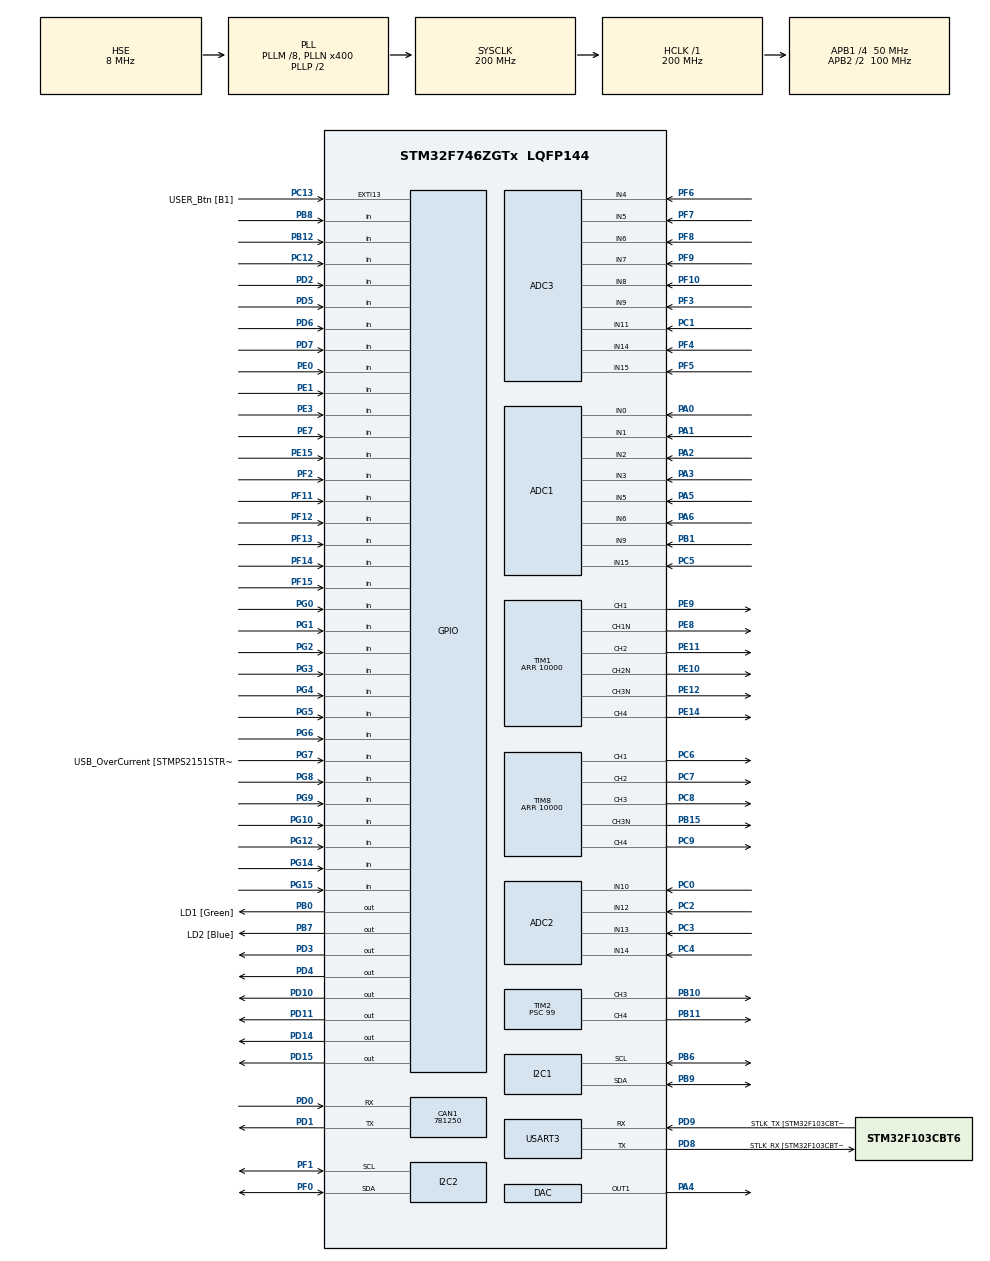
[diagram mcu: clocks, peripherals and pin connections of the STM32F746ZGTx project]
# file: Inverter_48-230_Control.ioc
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ADC1.Channel-0\#ChannelRegularConversion=ADC_CHANNEL_5
ADC1.ClockPrescaler=ADC_CLOCK_SYNC_PCLK_DIV6
ADC1.ContinuousConvMode=DISABLE
ADC1.DMAContinuousRequests=ENABLE
ADC1.DataAlign=ADC_DATAALIGN_RIGHT
ADC1.DiscontinuousConvMode=DISABLE
ADC1.EOCSelection=ADC_EOC_SEQ_CONV
ADC1.ExternalTrigConv=ADC_EXTERNALTRIGCONV_T1_TRGO2
ADC1.Mode=ADC_TRIPLEMODE_REGSIMULT
ADC1.NbrOfConversion=1
ADC1.NbrOfConversionFlag=1
ADC1.Rank-0\#ChannelRegularConversion=1
ADC1.SamplingTime-0\#ChannelRegularConversion=ADC_SAMPLETIME_15CYCLES
ADC1.ScanConvMode=ADC_SCAN_ENABLE
ADC1.master=1
ADC2.Channel-1\#ChannelRegularConversion=ADC_CHANNEL_14
ADC2.ClockPrescaler=ADC_CLOCK_SYNC_PCLK_DIV6
ADC2.DMAAccessMode=ADC_DMAACCESSMODE_1
ADC2.DataAlign=ADC_DATAALIGN_RIGHT
ADC2.EOCSelection=ADC_EOC_SEQ_CONV
ADC2.Mode=ADC_TRIPLEMODE_REGSIMULT
ADC2.NbrOfConversion=1
ADC2.NbrOfConversionFlag=1
ADC2.Rank-1\#ChannelRegularConversion=1
ADC2.SamplingTime-1\#ChannelRegularConversion=ADC_SAMPLETIME_15CYCLES
ADC2.ScanConvMode=ADC_SCAN_ENABLE
ADC3.Channel-1\#ChannelRegularConversion=ADC_CHANNEL_4
ADC3.ClockPrescaler=ADC_CLOCK_SYNC_PCLK_DIV6
ADC3.DMAAccessMode=ADC_DMAACCESSMODE_1
ADC3.DataAlign=ADC_DATAALIGN_RIGHT
ADC3.EOCSelection=ADC_EOC_SEQ_CONV
ADC3.Mode=ADC_TRIPLEMODE_REGSIMULT
ADC3.NbrOfConversion=1
ADC3.NbrOfConversionFlag=1
ADC3.Rank-1\#ChannelRegularConversion=1
ADC3.SamplingTime-1\#ChannelRegularConversion=ADC_SAMPLETIME_15CYCLES
ADC3.ScanConvMode=ADC_SCAN_ENABLE
CAN1.BS1=CAN_BS1_2TQ
CAN1.CalculateBaudRate=781250
CAN1.CalculateTimeBit=1280
CAN1.CalculateTimeQuantum=320.0
CORTEX_M7.ART_ACCELERATOR_ENABLE=1
CORTEX_M7.CPU_ICache=Enabled
CORTEX_M7.PREFETCH_ENABLE=1
Dma.ADC1.0.Direction=DMA_PERIPH_TO_MEMORY
Dma.ADC1.0.FIFOMode=DMA_FIFOMODE_DISABLE
Dma.ADC1.0.Instance=DMA2_Stream4
Dma.ADC1.0.MemDataAlignment=DMA_MDATAALIGN_HALFWORD
Dma.ADC1.0.MemInc=DMA_MINC_ENABLE
Dma.ADC1.0.Mode=DMA_CIRCULAR
Dma.ADC1.0.PeriphDataAlignment=DMA_PDATAALIGN_HALFWORD
Dma.ADC1.0.PeriphInc=DMA_PINC_DISABLE
Dma.ADC1.0.Priority=DMA_PRIORITY_LOW
Dma.Request0=ADC1
Dma.Request1=USART3_TX
Dma.USART3_TX.1.Direction=DMA_MEMORY_TO_PERIPH
Dma.USART3_TX.1.FIFOMode=DMA_FIFOMODE_DISABLE
Dma.USART3_TX.1.Instance=DMA1_Stream4
Dma.USART3_TX.1.MemDataAlignment=DMA_MDATAALIGN_BYTE
Dma.USART3_TX.1.MemInc=DMA_MINC_ENABLE
Dma.USART3_TX.1.Mode=DMA_NORMAL
Dma.USART3_TX.1.PeriphDataAlignment=DMA_PDATAALIGN_BYTE
Dma.USART3_TX.1.PeriphInc=DMA_PINC_DISABLE
Dma.USART3_TX.1.Priority=DMA_PRIORITY_LOW
I2C1.Timing=0x00C0EAFF
I2C2.Timing=0x00C0EAFF
Mcu.Family=STM32F7
Mcu.Name=STM32F746ZGTx
Mcu.Package=LQFP144
NVIC.DMA1_Stream4_IRQn=true\:0\:0\:false\:false\:true\:false\:true\:true
NVIC.DMA2_Stream4_IRQn=true\:0\:0\:false\:false\:true\:false\:true\:true
NVIC.PriorityGroup=NVIC_PRIORITYGROUP_4
NVIC.TIM8_TRG_COM_TIM14_IRQn=true\:7\:0\:true\:false\:true\:true\:true\:true
NVIC.USART3_IRQn=true\:0\:0\:false\:false\:true\:true\:true\:true
PA0/WKUP.Signal=ADCx_IN0
PA1.Signal=ADCx_IN1
PA10.GPIO_Label=USB_ID
PA10.Signal=USB_OTG_FS_ID
PA11.GPIO_Label=USB_DM
PA11.Signal=USB_OTG_FS_DM
PA12.GPIO_Label=USB_DP
PA12.Signal=USB_OTG_FS_DP
PA13.GPIO_Label=TMS
PA13.Signal=SYS_JTMS-SWDIO
PA14.GPIO_Label=TCK
PA14.Signal=SYS_JTCK-SWCLK
PA2.Signal=ADCx_IN2
PA3.Signal=ADCx_IN3
PA4.Signal=COMP_DAC1_group
PA5.Signal=ADCx_IN5
PA6.Signal=ADCx_IN6
PA7.Signal=TIM8_CH1N
PA8.GPIO_Label=USB_SOF [TP1]
PA8.Signal=USB_OTG_FS_SOF
PA9.GPIO_Label=USB_VBUS
PA9.Signal=USB_OTG_FS_VBUS
PB0.GPIO_Label=LD1 [Green]
PB0.Signal=GPIO_Output
PB1.Signal=ADCx_IN9
PB10.GPIO_ModeDefaultPP=GPIO_MODE_AF_OD
PB10.Signal=S_TIM2_CH3
PB11.GPIO_ModeDefaultPP=GPIO_MODE_AF_OD
PB11.Signal=S_TIM2_CH4
PB12.Signal=GPIO_Input
PB13.GPIO_Label=RMII_TXD1 [LAN8742A-CZ-TR_TXD1]
PB13.Signal=ETH_TXD1
PB14.Signal=TIM8_CH2N
PB15.Mode=PWM Generation3 CH3 CH3N
PB15.Signal=TIM8_CH3N
PB3.GPIO_Label=SW0
PB3.Signal=SYS_JTDO-SWO
PB4.Signal=S_TIM3_CH1
PB5.Signal=S_TIM3_CH2
PB6.Mode=I2C
PB6.Signal=I2C1_SCL
PB7.GPIO_Label=LD2 [Blue]
PB7.Signal=GPIO_Output
PB8.Signal=GPIO_Input
PB9.Mode=I2C
PB9.Signal=I2C1_SDA
PC0.Signal=ADCx_IN10
PC1.Signal=ADCx_IN11
PC12.Signal=GPIO_Input
PC13.GPIO_Label=USER_Btn [B1]
PC13.Signal=GPXTI13
PC14/OSC32_IN.Signal=RCC_OSC32_IN
PC15/OSC32_OUT.Signal=RCC_OSC32_OUT
PC2.Signal=ADCx_IN12
PC3.Signal=ADCx_IN13
PC4.Signal=ADCx_IN14
PC5.Signal=ADCx_IN15
PC6.Signal=S_TIM8_CH1
PC7.Signal=S_TIM8_CH2
PC8.Signal=S_TIM8_CH3
PC9.Signal=S_TIM8_CH4
PD0.Mode=CAN_Activate
PD0.Signal=CAN1_RX
PD1.Mode=CAN_Activate
PD1.Signal=CAN1_TX
PD10.GPIO_ModeDefaultOutputPP=GPIO_MODE_OUTPUT_PP
PD10.GPIO_PuPd=GPIO_NOPULL
PD10.Signal=GPIO_Output
PD11.Signal=GPIO_Output
PD14.Signal=GPIO_Output
PD15.Signal=GPIO_Output
PD2.Signal=GPIO_Input
PD3.Signal=GPIO_Output
PD4.Signal=GPIO_Output
PD5.Signal=GPIO_Input
PD6.Signal=GPIO_Input
PD7.Signal=GPIO_Input
PD8.GPIO_Label=STLK_RX [STM32F103CBT6_PA3]
PD8.Mode=Asynchronous
PD8.Signal=USART3_TX
PD9.GPIO_Label=STLK_TX [STM32F103CBT6_PA2]
PD9.Mode=Asynchronous
PD9.Signal=USART3_RX
PE0.Signal=GPIO_Input
PE1.Signal=GPIO_Input
PE10.Mode=PWM Generation2 CH2 CH2N
PE10.Signal=TIM1_CH2N
PE11.Signal=S_TIM1_CH2
PE12.Mode=PWM Generation3 CH3N
PE12.Signal=TIM1_CH3N
PE14.Signal=S_TIM1_CH4
PE15.Signal=GPIO_Input
PE3.Signal=GPIO_Input
PE7.Signal=GPIO_Input
PE8.Mode=PWM Generation1 CH1 CH1N
PE8.Signal=TIM1_CH1N
PE9.Signal=S_TIM1_CH1
PF0.Mode=I2C
PF0.Signal=I2C2_SDA
PF1.Mode=I2C
PF1.Signal=I2C2_SCL
PF10.Mode=IN8
PF10.Signal=ADC3_IN8
PF11.Signal=GPIO_Input
PF12.Signal=GPIO_Input
PF13.Signal=GPIO_Input
PF14.Signal=GPIO_Input
PF15.Signal=GPIO_Input
PF2.Signal=GPIO_Input
PF3.Mode=IN9
PF3.Signal=ADC3_IN9
PF4.Mode=IN14
PF4.Signal=ADC3_IN14
PF5.Mode=IN15
PF5.Signal=ADC3_IN15
PF6.Mode=IN4
PF6.Signal=ADC3_IN4
PF7.Mode=IN5
PF7.Signal=ADC3_IN5
PF8.Mode=IN6
PF8.Signal=ADC3_IN6
PF9.Mode=IN7
PF9.Signal=ADC3_IN7
PG0.Signal=GPIO_Input
PG1.Signal=GPIO_Input
PG10.Signal=GPIO_Input
PG11.GPIO_Label=RMII_TX_EN [LAN8742A-CZ-TR_TXEN]
PG11.Signal=ETH_TX_EN
PG12.Signal=GPIO_Input
PG13.GPIO_Label=RMII_TXD0 [LAN8742A-CZ-TR_TXD0]
PG13.Signal=ETH_TXD0
PG14.Signal=GPIO_Input
PG15.Signal=GPIO_Input
PG2.Signal=GPIO_Input
PG3.Signal=GPIO_Input
PG4.Signal=GPIO_Input
PG5.Signal=GPIO_Input
PG6.Signal=GPIO_Input
PG7.GPIO_Label=USB_OverCurrent [STMPS2151STR_FAULT]
PG7.Signal=GPIO_Input
PG8.Signal=GPIO_Input
PG9.Signal=GPIO_Input
PH0/OSC_IN.GPIO_Label=MCO [STM32F103CBT6_PA8]
PH0/OSC_IN.Mode=HSE-External-Clock-Source
PH0/OSC_IN.Signal=RCC_OSC_IN
PH1/OSC_OUT.Mode=HSE-External-Clock-Source
PH1/OSC_OUT.Signal=RCC_OSC_OUT
ProjectManager.HeapSize=0x200
ProjectManager.StackSize=0x400
ProjectManager.TargetToolchain=STM32CubeIDE
RCC.48MHZClocksFreq_Value=24000000
RCC.AHBFreq_Value=200000000
RCC.APB1CLKDivider=RCC_HCLK_DIV4
RCC.APB1Freq_Value=50000000
RCC.APB1TimFreq_Value=100000000
RCC.APB2CLKDivider=RCC_HCLK_DIV2
RCC.APB2Freq_Value=100000000
RCC.APB2TimFreq_Value=200000000
RCC.CortexFreq_Value=200000000
RCC.HCLKFreq_Value=200000000
RCC.HSE_VALUE=8000000
RCC.HSI_VALUE=16000000
RCC.LSE_VALUE=32768
RCC.PLLM=8
RCC.PLLMUL=RCC_PLL_MUL9
RCC.PLLN=400
RCC.PLLSourceVirtual=RCC_PLLSOURCE_HSE
RCC.PRESCALERUSB=RCC_USBCLKSOURCE_PLL_DIV1_5
RCC.SYSCLKFreq_VALUE=200000000
RCC.SYSCLKSource=RCC_SYSCLKSOURCE_PLLCLK
RCC.SYSCLKSourceVirtual=RCC_SYSCLKSOURCE_PLLCLK
RCC.USBFreq_Value=200000000
RCC.VCOOutputFreq_Value=400000000
SH.ADCx_IN0.0=ADC1_IN0,IN0
SH.ADCx_IN0.1=ADC2_IN0,IN0
SH.ADCx_IN0.2=ADC3_IN0,IN0
SH.ADCx_IN1.0=ADC1_IN1,IN1
SH.ADCx_IN1.1=ADC2_IN1,IN1
SH.ADCx_IN1.2=ADC3_IN1,IN1
SH.ADCx_IN10.0=ADC2_IN10,IN10
SH.ADCx_IN10.1=ADC3_IN10,IN10
SH.ADCx_IN10.2=ADC1_IN10,IN10
SH.ADCx_IN11.0=ADC3_IN11,IN11
SH.ADCx_IN11.1=ADC2_IN11,IN11
SH.ADCx_IN11.2=ADC1_IN11,IN11
SH.ADCx_IN12.0=ADC2_IN12,IN12
SH.ADCx_IN12.1=ADC3_IN12,IN12
SH.ADCx_IN12.2=ADC1_IN12,IN12
SH.ADCx_IN13.0=ADC2_IN13,IN13
SH.ADCx_IN13.1=ADC3_IN13,IN13
SH.ADCx_IN13.2=ADC1_IN13,IN13
SH.ADCx_IN14.0=ADC2_IN14,IN14
SH.ADCx_IN15.0=ADC1_IN15,IN15
SH.ADCx_IN15.1=ADC2_IN15,IN15
SH.ADCx_IN2.0=ADC1_IN2,IN2
SH.ADCx_IN2.1=ADC3_IN2,IN2
SH.ADCx_IN2.2=ADC2_IN2,IN2
SH.ADCx_IN3.0=ADC1_IN3,IN3
SH.ADCx_IN3.1=ADC3_IN3,IN3
SH.ADCx_IN3.2=ADC2_IN3,IN3
SH.ADCx_IN5.0=ADC1_IN5,IN5
SH.ADCx_IN6.0=ADC1_IN6,IN6
SH.ADCx_IN6.1=ADC2_IN6,IN6
SH.ADCx_IN9.0=ADC1_IN9,IN9
SH.ADCx_IN9.1=ADC2_IN9,IN9
SH.COMP_DAC1_group.0=DAC_OUT1,DAC_OUT1
SH.S_TIM1_CH1.0=TIM1_CH1,PWM Generation1 CH1 CH1N
SH.S_TIM1_CH2.0=TIM1_CH2,PWM Generation2 CH2 CH2N
SH.S_TIM1_CH4.0=TIM1_CH4,PWM Generation4 CH4
SH.S_TIM2_CH3.0=TIM2_CH3,PWM Generation3 CH3
SH.S_TIM2_CH4.0=TIM2_CH4,PWM Generation4 CH4
SH.S_TIM3_CH1.0=TIM3_CH1
SH.S_TIM3_CH2.0=TIM3_CH2
SH.S_TIM8_CH1.0=TIM8_CH1,PWM Generation1 CH1
SH.S_TIM8_CH2.0=TIM8_CH2,PWM Generation2 CH2
SH.S_TIM8_CH3.0=TIM8_CH3,PWM Generation3 CH3 CH3N
SH.S_TIM8_CH4.0=TIM8_CH4,PWM Generation4 CH4
TIM1.BreakFilter=1
TIM1.Channel-PWM\ Generation1\ CH1\ CH1N=TIM_CHANNEL_1
TIM1.Channel-PWM\ Generation2\ CH2\ CH2N=TIM_CHANNEL_2
TIM1.Channel-PWM\ Generation3\ CH3N=TIM_CHANNEL_3
TIM1.Channel-PWM\ Generation4\ CH4=TIM_CHANNEL_4
TIM1.CounterMode=TIM_COUNTERMODE_CENTERALIGNED1
TIM1.DeadTime=230
TIM1.OCMode_PWM-PWM\ Generation4\ CH4=TIM_OCMODE_PWM1
TIM1.Period=10000
TIM1.TIM_MasterOutputTrigger=TIM_TRGO_ENABLE
TIM1.TIM_MasterOutputTrigger2=TIM_TRGO2_UPDATE
TIM1.TIM_MasterSlaveMode=TIM_MASTERSLAVEMODE_ENABLE
TIM2.Channel-PWM\ Generation3\ CH3=TIM_CHANNEL_3
TIM2.Channel-PWM\ Generation4\ CH4=TIM_CHANNEL_4
TIM2.Period=199
TIM2.Prescaler=99
TIM2.Pulse-PWM\ Generation3\ CH3=100
TIM8.Break2Filter=0
TIM8.BreakFilter=1
TIM8.Channel-PWM\ Generation1\ CH1=TIM_CHANNEL_1
TIM8.Channel-PWM\ Generation2\ CH2=TIM_CHANNEL_2
TIM8.Channel-PWM\ Generation3\ CH3\ CH3N=TIM_CHANNEL_3
TIM8.Channel-PWM\ Generation4\ CH4=TIM_CHANNEL_4
TIM8.CounterMode=TIM_COUNTERMODE_CENTERALIGNED1
TIM8.DeadTime=230
TIM8.OCMode_PWM-PWM\ Generation4\ CH4=TIM_OCMODE_PWM1
TIM8.Period=10000
TIM8.TIM_MasterSlaveMode=TIM_MASTERSLAVEMODE_ENABLE
USART3.VirtualMode-Asynchronous=VM_ASYNC
USART3.WordLength=WORDLENGTH_8B
VP_TIM8_VS_ClockSourceITR.Mode=TriggerSource_ITR0
VP_TIM8_VS_ControllerModeTrigger.Mode=Trigger Mode
board=NUCLEO-F746ZG

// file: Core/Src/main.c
/* USER CODE BEGIN Header */
/**
  ******************************************************************************
  * @file           : main.c
  * @brief          : Main program body
  ******************************************************************************
  * @attention
  *
  * Copyright (c) 2023 STMicroelectronics.
  * All rights reserved.
  *
  * This software is licensed under terms that can be found in the LICENSE file
  * in the root directory of this software component.
  * If no LICENSE file comes with this software, it is provided AS-IS.
  *
  ******************************************************************************
  */
#include "power_converter_control_system.h"

/* USER CODE END Header */
#include "main.h"

ADC_HandleTypeDef hadc1;
ADC_HandleTypeDef hadc2;
ADC_HandleTypeDef hadc3;
DMA_HandleTypeDef hdma_adc1;

CAN_HandleTypeDef hcan1;

DAC_HandleTypeDef hdac;

I2C_HandleTypeDef hi2c1;
I2C_HandleTypeDef hi2c2;

TIM_HandleTypeDef htim1;
TIM_HandleTypeDef htim2;
TIM_HandleTypeDef htim8;

UART_HandleTypeDef huart3;
DMA_HandleTypeDef hdma_usart3_tx;

void SystemClock_Config(void);
static void MX_GPIO_Init(void);
static void MX_DMA_Init(void);
static void MX_ADC1_Init(void);
static void MX_TIM1_Init(void);
static void MX_USART3_UART_Init(void);
static void MX_ADC2_Init(void);
static void MX_ADC3_Init(void);
static void MX_TIM8_Init(void);
static void MX_I2C1_Init(void);
static void MX_CAN1_Init(void);
static void MX_I2C2_Init(void);
static void MX_TIM2_Init(void);
static void MX_DAC_Init(void);

int main(void)
{
/* Enable the CPU Cache */

  /* Enable I-Cache---------------------------------------------------------*/
  SCB_EnableICache();

  /* MCU Configuration--------------------------------------------------------*/

  /* Reset of all peripherals, Initializes the Flash interface and the Systick. */
  HAL_Init();

  /* USER CODE BEGIN Init */

  //__HAL_RCC_DBGMCU_CLK_DISABLE();
  //HAL_RCC_DBGMCU_CLK_DISABLE();

  DBGMCU->APB2FZ |= DBGMCU_APB2_FZ_DBG_TIM1_STOP|DBGMCU_APB2_FZ_DBG_TIM8_STOP;

  /* USER CODE END Init */

  /* Configure the system clock */
  SystemClock_Config();

  /* Initialize all configured peripherals */
  MX_GPIO_Init();
  MX_DMA_Init();
  MX_ADC1_Init();
  MX_TIM1_Init();
  MX_USART3_UART_Init();
  MX_ADC2_Init();
  MX_ADC3_Init();
  MX_TIM8_Init();
  MX_I2C1_Init();
  MX_CAN1_Init();
  MX_I2C2_Init();
  MX_TIM2_Init();
  MX_DAC_Init();
  /* USER CODE BEGIN 2 */

  InitConverterControlSystemPeripherals();

  /* USER CODE END 2 */

  /* Infinite loop */
  while (1)
  {

    /* USER CODE BEGIN 3 */
	IdleProcess();
  }
  /* USER CODE END 3 */
}

void SystemClock_Config(void)
{
  RCC_OscInitTypeDef RCC_OscInitStruct = {0};
  RCC_ClkInitTypeDef RCC_ClkInitStruct = {0};

  /** Configure the main internal regulator output voltage
  */
  __HAL_RCC_PWR_CLK_ENABLE();
  __HAL_PWR_VOLTAGESCALING_CONFIG(PWR_REGULATOR_VOLTAGE_SCALE1);

  /** Initializes the RCC Oscillators according to the specified parameters
  * in the RCC_OscInitTypeDef structure.
  */
  RCC_OscInitStruct.OscillatorType = RCC_OSCILLATORTYPE_HSE;
  RCC_OscInitStruct.HSEState = RCC_HSE_BYPASS;
  RCC_OscInitStruct.PLL.PLLState = RCC_PLL_ON;
  RCC_OscInitStruct.PLL.PLLSource = RCC_PLLSOURCE_HSE;
  RCC_OscInitStruct.PLL.PLLM = 8;
  RCC_OscInitStruct.PLL.PLLN = 400;
  RCC_OscInitStruct.PLL.PLLP = RCC_PLLP_DIV2;
  RCC_OscInitStruct.PLL.PLLQ = 2;
  if (HAL_RCC_OscConfig(&RCC_OscInitStruct) != HAL_OK)
  {
    Error_Handler();
  }

  /** Activate the Over-Drive mode
  */
  if (HAL_PWREx_EnableOverDrive() != HAL_OK)
  {
    Error_Handler();
  }

  /** Initializes the CPU, AHB and APB buses clocks
  */
  RCC_ClkInitStruct.ClockType = RCC_CLOCKTYPE_HCLK|RCC_CLOCKTYPE_SYSCLK
                              |RCC_CLOCKTYPE_PCLK1|RCC_CLOCKTYPE_PCLK2;
  RCC_ClkInitStruct.SYSCLKSource = RCC_SYSCLKSOURCE_PLLCLK;
  RCC_ClkInitStruct.AHBCLKDivider = RCC_SYSCLK_DIV1;
  RCC_ClkInitStruct.APB1CLKDivider = RCC_HCLK_DIV4;
  RCC_ClkInitStruct.APB2CLKDivider = RCC_HCLK_DIV2;

  if (HAL_RCC_ClockConfig(&RCC_ClkInitStruct, FLASH_LATENCY_6) != HAL_OK)
  {
    Error_Handler();
  }
}

static void MX_ADC1_Init(void)
{

  ADC_MultiModeTypeDef multimode = {0};
  ADC_ChannelConfTypeDef sConfig = {0};

  /** Configure the global features of the ADC (Clock, Resolution, Data Alignment and number of conversion)
  */
  hadc1.Instance = ADC1;
  hadc1.Init.ClockPrescaler = ADC_CLOCK_SYNC_PCLK_DIV6;
  hadc1.Init.Resolution = ADC_RESOLUTION_12B;
  hadc1.Init.ScanConvMode = ADC_SCAN_ENABLE;
  hadc1.Init.ContinuousConvMode = DISABLE;
  hadc1.Init.DiscontinuousConvMode = DISABLE;
  hadc1.Init.ExternalTrigConvEdge = ADC_EXTERNALTRIGCONVEDGE_RISING;
  hadc1.Init.ExternalTrigConv = ADC_EXTERNALTRIGCONV_T1_TRGO2;
  hadc1.Init.DataAlign = ADC_DATAALIGN_RIGHT;
  hadc1.Init.NbrOfConversion = 1;
  hadc1.Init.DMAContinuousRequests = ENABLE;
  hadc1.Init.EOCSelection = ADC_EOC_SEQ_CONV;
  if (HAL_ADC_Init(&hadc1) != HAL_OK)
  {
    Error_Handler();
  }

  /** Configure the ADC multi-mode
  */
  multimode.Mode = ADC_TRIPLEMODE_REGSIMULT;
  multimode.DMAAccessMode = ADC_DMAACCESSMODE_1;
  multimode.TwoSamplingDelay = ADC_TWOSAMPLINGDELAY_5CYCLES;
  if (HAL_ADCEx_MultiModeConfigChannel(&hadc1, &multimode) != HAL_OK)
  {
    Error_Handler();
  }

  /** Configure for the selected ADC regular channel its corresponding rank in the sequencer and its sample time.
  */
  sConfig.Channel = ADC_CHANNEL_5;
  sConfig.Rank = ADC_REGULAR_RANK_1;
  sConfig.SamplingTime = ADC_SAMPLETIME_15CYCLES;
  if (HAL_ADC_ConfigChannel(&hadc1, &sConfig) != HAL_OK)
  {
    Error_Handler();
  }

}

static void MX_ADC2_Init(void)
{

  ADC_ChannelConfTypeDef sConfig = {0};

  /** Configure the global features of the ADC (Clock, Resolution, Data Alignment and number of conversion)
  */
  hadc2.Instance = ADC2;
  hadc2.Init.ClockPrescaler = ADC_CLOCK_SYNC_PCLK_DIV6;
  hadc2.Init.Resolution = ADC_RESOLUTION_12B;
  hadc2.Init.ScanConvMode = ADC_SCAN_ENABLE;
  hadc2.Init.ContinuousConvMode = DISABLE;
  hadc2.Init.DiscontinuousConvMode = DISABLE;
  hadc2.Init.DataAlign = ADC_DATAALIGN_RIGHT;
  hadc2.Init.NbrOfConversion = 1;
  hadc2.Init.DMAContinuousRequests = DISABLE;
  hadc2.Init.EOCSelection = ADC_EOC_SEQ_CONV;
  if (HAL_ADC_Init(&hadc2) != HAL_OK)
  {
    Error_Handler();
  }

  /** Configure for the selected ADC regular channel its corresponding rank in the sequencer and its sample time.
  */
  sConfig.Channel = ADC_CHANNEL_14;
  sConfig.Rank = ADC_REGULAR_RANK_1;
  sConfig.SamplingTime = ADC_SAMPLETIME_15CYCLES;
  if (HAL_ADC_ConfigChannel(&hadc2, &sConfig) != HAL_OK)
  {
    Error_Handler();
  }

}

static void MX_ADC3_Init(void)
{

  ADC_ChannelConfTypeDef sConfig = {0};

  /** Configure the global features of the ADC (Clock, Resolution, Data Alignment and number of conversion)
  */
  hadc3.Instance = ADC3;
  hadc3.Init.ClockPrescaler = ADC_CLOCK_SYNC_PCLK_DIV6;
  hadc3.Init.Resolution = ADC_RESOLUTION_12B;
  hadc3.Init.ScanConvMode = ADC_SCAN_ENABLE;
  hadc3.Init.ContinuousConvMode = DISABLE;
  hadc3.Init.DiscontinuousConvMode = DISABLE;
  hadc3.Init.DataAlign = ADC_DATAALIGN_RIGHT;
  hadc3.Init.NbrOfConversion = 1;
  hadc3.Init.DMAContinuousRequests = DISABLE;
  hadc3.Init.EOCSelection = ADC_EOC_SEQ_CONV;
  if (HAL_ADC_Init(&hadc3) != HAL_OK)
  {
    Error_Handler();
  }

  /** Configure for the selected ADC regular channel its corresponding rank in the sequencer and its sample time.
  */
  sConfig.Channel = ADC_CHANNEL_4;
  sConfig.Rank = ADC_REGULAR_RANK_1;
  sConfig.SamplingTime = ADC_SAMPLETIME_15CYCLES;
  if (HAL_ADC_ConfigChannel(&hadc3, &sConfig) != HAL_OK)
  {
    Error_Handler();
  }

}

static void MX_CAN1_Init(void)
{

  hcan1.Instance = CAN1;
  hcan1.Init.Prescaler = 16;
  hcan1.Init.Mode = CAN_MODE_NORMAL;
  hcan1.Init.SyncJumpWidth = CAN_SJW_1TQ;
  hcan1.Init.TimeSeg1 = CAN_BS1_2TQ;
  hcan1.Init.TimeSeg2 = CAN_BS2_1TQ;
  hcan1.Init.TimeTriggeredMode = DISABLE;
  hcan1.Init.AutoBusOff = DISABLE;
  hcan1.Init.AutoWakeUp = DISABLE;
  hcan1.Init.AutoRetransmission = DISABLE;
  hcan1.Init.ReceiveFifoLocked = DISABLE;
  hcan1.Init.TransmitFifoPriority = DISABLE;
  if (HAL_CAN_Init(&hcan1) != HAL_OK)
  {
    Error_Handler();
  }

}

static void MX_DAC_Init(void)
{

  DAC_ChannelConfTypeDef sConfig = {0};

  /** DAC Initialization
  */
  hdac.Instance = DAC;
  if (HAL_DAC_Init(&hdac) != HAL_OK)
  {
    Error_Handler();
  }

  /** DAC channel OUT1 config
  */
  sConfig.DAC_Trigger = DAC_TRIGGER_NONE;
  sConfig.DAC_OutputBuffer = DAC_OUTPUTBUFFER_ENABLE;
  if (HAL_DAC_ConfigChannel(&hdac, &sConfig, DAC_CHANNEL_1) != HAL_OK)
  {
    Error_Handler();
  }

}

static void MX_I2C1_Init(void)
{

  hi2c1.Instance = I2C1;
  hi2c1.Init.Timing = 0x00C0EAFF;
  hi2c1.Init.OwnAddress1 = 0;
  hi2c1.Init.AddressingMode = I2C_ADDRESSINGMODE_7BIT;
  hi2c1.Init.DualAddressMode = I2C_DUALADDRESS_DISABLE;
  hi2c1.Init.OwnAddress2 = 0;
  hi2c1.Init.OwnAddress2Masks = I2C_OA2_NOMASK;
  hi2c1.Init.GeneralCallMode = I2C_GENERALCALL_DISABLE;
  hi2c1.Init.NoStretchMode = I2C_NOSTRETCH_DISABLE;
  if (HAL_I2C_Init(&hi2c1) != HAL_OK)
  {
    Error_Handler();
  }

  /** Configure Analogue filter
  */
  if (HAL_I2CEx_ConfigAnalogFilter(&hi2c1, I2C_ANALOGFILTER_ENABLE) != HAL_OK)
  {
    Error_Handler();
  }

  /** Configure Digital filter
  */
  if (HAL_I2CEx_ConfigDigitalFilter(&hi2c1, 0) != HAL_OK)
  {
    Error_Handler();
  }

}

static void MX_I2C2_Init(void)
{

  hi2c2.Instance = I2C2;
  hi2c2.Init.Timing = 0x00C0EAFF;
  hi2c2.Init.OwnAddress1 = 0;
  hi2c2.Init.AddressingMode = I2C_ADDRESSINGMODE_7BIT;
  hi2c2.Init.DualAddressMode = I2C_DUALADDRESS_DISABLE;
  hi2c2.Init.OwnAddress2 = 0;
  hi2c2.Init.OwnAddress2Masks = I2C_OA2_NOMASK;
  hi2c2.Init.GeneralCallMode = I2C_GENERALCALL_DISABLE;
  hi2c2.Init.NoStretchMode = I2C_NOSTRETCH_DISABLE;
  if (HAL_I2C_Init(&hi2c2) != HAL_OK)
  {
    Error_Handler();
  }

  /** Configure Analogue filter
  */
  if (HAL_I2CEx_ConfigAnalogFilter(&hi2c2, I2C_ANALOGFILTER_ENABLE) != HAL_OK)
  {
    Error_Handler();
  }

  /** Configure Digital filter
  */
  if (HAL_I2CEx_ConfigDigitalFilter(&hi2c2, 0) != HAL_OK)
  {
    Error_Handler();
  }

}

static void MX_TIM1_Init(void)
{

  TIM_MasterConfigTypeDef sMasterConfig = {0};
  TIM_OC_InitTypeDef sConfigOC = {0};
  TIM_BreakDeadTimeConfigTypeDef sBreakDeadTimeConfig = {0};

  htim1.Instance = TIM1;
  htim1.Init.Prescaler = 0;
  htim1.Init.CounterMode = TIM_COUNTERMODE_CENTERALIGNED1;
  htim1.Init.Period = 10000;
  htim1.Init.ClockDivision = TIM_CLOCKDIVISION_DIV1;
  htim1.Init.RepetitionCounter = 0;
  htim1.Init.AutoReloadPreload = TIM_AUTORELOAD_PRELOAD_DISABLE;
  if (HAL_TIM_PWM_Init(&htim1) != HAL_OK)
  {
    Error_Handler();
  }
  sMasterConfig.MasterOutputTrigger = TIM_TRGO_ENABLE;
  sMasterConfig.MasterOutputTrigger2 = TIM_TRGO2_UPDATE;
  sMasterConfig.MasterSlaveMode = TIM_MASTERSLAVEMODE_ENABLE;
  if (HAL_TIMEx_MasterConfigSynchronization(&htim1, &sMasterConfig) != HAL_OK)
  {
    Error_Handler();
  }
  sConfigOC.OCMode = TIM_OCMODE_PWM1;
  sConfigOC.Pulse = 0;
  sConfigOC.OCPolarity = TIM_OCPOLARITY_HIGH;
  sConfigOC.OCNPolarity = TIM_OCNPOLARITY_HIGH;
  sConfigOC.OCFastMode = TIM_OCFAST_DISABLE;
  sConfigOC.OCIdleState = TIM_OCIDLESTATE_RESET;
  sConfigOC.OCNIdleState = TIM_OCNIDLESTATE_RESET;
  if (HAL_TIM_PWM_ConfigChannel(&htim1, &sConfigOC, TIM_CHANNEL_1) != HAL_OK)
  {
    Error_Handler();
  }
  if (HAL_TIM_PWM_ConfigChannel(&htim1, &sConfigOC, TIM_CHANNEL_2) != HAL_OK)
  {
    Error_Handler();
  }
  if (HAL_TIM_PWM_ConfigChannel(&htim1, &sConfigOC, TIM_CHANNEL_3) != HAL_OK)
  {
    Error_Handler();
  }
  if (HAL_TIM_PWM_ConfigChannel(&htim1, &sConfigOC, TIM_CHANNEL_4) != HAL_OK)
  {
    Error_Handler();
  }
  sBreakDeadTimeConfig.OffStateRunMode = TIM_OSSR_DISABLE;
  sBreakDeadTimeConfig.OffStateIDLEMode = TIM_OSSI_DISABLE;
  sBreakDeadTimeConfig.LockLevel = TIM_LOCKLEVEL_OFF;
  sBreakDeadTimeConfig.DeadTime = 230;
  sBreakDeadTimeConfig.BreakState = TIM_BREAK_DISABLE;
  sBreakDeadTimeConfig.BreakPolarity = TIM_BREAKPOLARITY_HIGH;
  sBreakDeadTimeConfig.BreakFilter = 1;
  sBreakDeadTimeConfig.Break2State = TIM_BREAK2_DISABLE;
  sBreakDeadTimeConfig.Break2Polarity = TIM_BREAK2POLARITY_HIGH;
  sBreakDeadTimeConfig.Break2Filter = 0;
  sBreakDeadTimeConfig.AutomaticOutput = TIM_AUTOMATICOUTPUT_DISABLE;
  if (HAL_TIMEx_ConfigBreakDeadTime(&htim1, &sBreakDeadTimeConfig) != HAL_OK)
  {
    Error_Handler();
  }
  HAL_TIM_MspPostInit(&htim1);

}

static void MX_TIM2_Init(void)
{

  TIM_MasterConfigTypeDef sMasterConfig = {0};
  TIM_OC_InitTypeDef sConfigOC = {0};

  htim2.Instance = TIM2;
  htim2.Init.Prescaler = 99;
  htim2.Init.CounterMode = TIM_COUNTERMODE_UP;
  htim2.Init.Period = 199;
  htim2.Init.ClockDivision = TIM_CLOCKDIVISION_DIV1;
  htim2.Init.AutoReloadPreload = TIM_AUTORELOAD_PRELOAD_DISABLE;
  if (HAL_TIM_PWM_Init(&htim2) != HAL_OK)
  {
    Error_Handler();
  }
  sMasterConfig.MasterOutputTrigger = TIM_TRGO_RESET;
  sMasterConfig.MasterSlaveMode = TIM_MASTERSLAVEMODE_DISABLE;
  if (HAL_TIMEx_MasterConfigSynchronization(&htim2, &sMasterConfig) != HAL_OK)
  {
    Error_Handler();
  }
  sConfigOC.OCMode = TIM_OCMODE_PWM1;
  sConfigOC.Pulse = 100;
  sConfigOC.OCPolarity = TIM_OCPOLARITY_HIGH;
  sConfigOC.OCFastMode = TIM_OCFAST_DISABLE;
  if (HAL_TIM_PWM_ConfigChannel(&htim2, &sConfigOC, TIM_CHANNEL_3) != HAL_OK)
  {
    Error_Handler();
  }
  sConfigOC.Pulse = 0;
  if (HAL_TIM_PWM_ConfigChannel(&htim2, &sConfigOC, TIM_CHANNEL_4) != HAL_OK)
  {
    Error_Handler();
  }
  HAL_TIM_MspPostInit(&htim2);

}

static void MX_TIM8_Init(void)
{

  TIM_SlaveConfigTypeDef sSlaveConfig = {0};
  TIM_MasterConfigTypeDef sMasterConfig = {0};
  TIM_OC_InitTypeDef sConfigOC = {0};
  TIM_BreakDeadTimeConfigTypeDef sBreakDeadTimeConfig = {0};

  htim8.Instance = TIM8;
  htim8.Init.Prescaler = 0;
  htim8.Init.CounterMode = TIM_COUNTERMODE_CENTERALIGNED1;
  htim8.Init.Period = 10000;
  htim8.Init.ClockDivision = TIM_CLOCKDIVISION_DIV1;
  htim8.Init.RepetitionCounter = 0;
  htim8.Init.AutoReloadPreload = TIM_AUTORELOAD_PRELOAD_DISABLE;
  if (HAL_TIM_Base_Init(&htim8) != HAL_OK)
  {
    Error_Handler();
  }
  if (HAL_TIM_PWM_Init(&htim8) != HAL_OK)
  {
    Error_Handler();
  }
  sSlaveConfig.SlaveMode = TIM_SLAVEMODE_TRIGGER;
  sSlaveConfig.InputTrigger = TIM_TS_ITR0;
  if (HAL_TIM_SlaveConfigSynchro(&htim8, &sSlaveConfig) != HAL_OK)
  {
    Error_Handler();
  }
  sMasterConfig.MasterOutputTrigger = TIM_TRGO_RESET;
  sMasterConfig.MasterOutputTrigger2 = TIM_TRGO2_RESET;
  sMasterConfig.MasterSlaveMode = TIM_MASTERSLAVEMODE_ENABLE;
  if (HAL_TIMEx_MasterConfigSynchronization(&htim8, &sMasterConfig) != HAL_OK)
  {
    Error_Handler();
  }
  sConfigOC.OCMode = TIM_OCMODE_PWM1;
  sConfigOC.Pulse = 0;
  sConfigOC.OCPolarity = TIM_OCPOLARITY_HIGH;
  sConfigOC.OCNPolarity = TIM_OCNPOLARITY_HIGH;
  sConfigOC.OCFastMode = TIM_OCFAST_DISABLE;
  sConfigOC.OCIdleState = TIM_OCIDLESTATE_RESET;
  sConfigOC.OCNIdleState = TIM_OCNIDLESTATE_RESET;
  if (HAL_TIM_PWM_ConfigChannel(&htim8, &sConfigOC, TIM_CHANNEL_1) != HAL_OK)
  {
    Error_Handler();
  }
  if (HAL_TIM_PWM_ConfigChannel(&htim8, &sConfigOC, TIM_CHANNEL_2) != HAL_OK)
  {
    Error_Handler();
  }
  if (HAL_TIM_PWM_ConfigChannel(&htim8, &sConfigOC, TIM_CHANNEL_3) != HAL_OK)
  {
    Error_Handler();
  }
  if (HAL_TIM_PWM_ConfigChannel(&htim8, &sConfigOC, TIM_CHANNEL_4) != HAL_OK)
  {
    Error_Handler();
  }
  sBreakDeadTimeConfig.OffStateRunMode = TIM_OSSR_DISABLE;
  sBreakDeadTimeConfig.OffStateIDLEMode = TIM_OSSI_DISABLE;
  sBreakDeadTimeConfig.LockLevel = TIM_LOCKLEVEL_OFF;
  sBreakDeadTimeConfig.DeadTime = 230;
  sBreakDeadTimeConfig.BreakState = TIM_BREAK_DISABLE;
  sBreakDeadTimeConfig.BreakPolarity = TIM_BREAKPOLARITY_HIGH;
  sBreakDeadTimeConfig.BreakFilter = 1;
  sBreakDeadTimeConfig.Break2State = TIM_BREAK2_DISABLE;
  sBreakDeadTimeConfig.Break2Polarity = TIM_BREAK2POLARITY_HIGH;
  sBreakDeadTimeConfig.Break2Filter = 0;
  sBreakDeadTimeConfig.AutomaticOutput = TIM_AUTOMATICOUTPUT_DISABLE;
  if (HAL_TIMEx_ConfigBreakDeadTime(&htim8, &sBreakDeadTimeConfig) != HAL_OK)
  {
    Error_Handler();
  }
  HAL_TIM_MspPostInit(&htim8);

}

static void MX_USART3_UART_Init(void)
{

  huart3.Instance = USART3;
  huart3.Init.BaudRate = 115200;
  huart3.Init.WordLength = UART_WORDLENGTH_8B;
  huart3.Init.StopBits = UART_STOPBITS_1;
  huart3.Init.Parity = UART_PARITY_NONE;
  huart3.Init.Mode = UART_MODE_TX_RX;
  huart3.Init.HwFlowCtl = UART_HWCONTROL_NONE;
  huart3.Init.OverSampling = UART_OVERSAMPLING_16;
  huart3.Init.OneBitSampling = UART_ONE_BIT_SAMPLE_DISABLE;
  huart3.AdvancedInit.AdvFeatureInit = UART_ADVFEATURE_NO_INIT;
  if (HAL_UART_Init(&huart3) != HAL_OK)
  {
    Error_Handler();
  }

}

static void MX_DMA_Init(void)
{

  /* DMA controller clock enable */
  __HAL_RCC_DMA2_CLK_ENABLE();
  __HAL_RCC_DMA1_CLK_ENABLE();

  /* DMA interrupt init */
  /* DMA1_Stream4_IRQn interrupt configuration */
  HAL_NVIC_SetPriority(DMA1_Stream4_IRQn, 0, 0);
  HAL_NVIC_EnableIRQ(DMA1_Stream4_IRQn);
  /* DMA2_Stream4_IRQn interrupt configuration */
  HAL_NVIC_SetPriority(DMA2_Stream4_IRQn, 0, 0);
  HAL_NVIC_EnableIRQ(DMA2_Stream4_IRQn);

}

static void MX_GPIO_Init(void)
{
  GPIO_InitTypeDef GPIO_InitStruct = {0};

  /* GPIO Ports Clock Enable */
  __HAL_RCC_GPIOE_CLK_ENABLE();
  __HAL_RCC_GPIOC_CLK_ENABLE();
  __HAL_RCC_GPIOF_CLK_ENABLE();
  __HAL_RCC_GPIOH_CLK_ENABLE();
  __HAL_RCC_GPIOA_CLK_ENABLE();
  __HAL_RCC_GPIOB_CLK_ENABLE();
  __HAL_RCC_GPIOG_CLK_ENABLE();
  __HAL_RCC_GPIOD_CLK_ENABLE();

  /*Configure GPIO pin Output Level */
  HAL_GPIO_WritePin(GPIOB, LD1_Pin|LD2_Pin, GPIO_PIN_RESET);

  /*Configure GPIO pin Output Level */
  HAL_GPIO_WritePin(GPIOD, GPIO_PIN_10|GPIO_PIN_11|GPIO_PIN_14|GPIO_PIN_15
                          |GPIO_PIN_3|GPIO_PIN_4, GPIO_PIN_RESET);

  /*Configure GPIO pins : PE3 PE7 PE15 PE0
                           PE1 */
  GPIO_InitStruct.Pin = GPIO_PIN_3|GPIO_PIN_7|GPIO_PIN_15|GPIO_PIN_0
                          |GPIO_PIN_1;
  GPIO_InitStruct.Mode = GPIO_MODE_INPUT;
  GPIO_InitStruct.Pull = GPIO_NOPULL;
  HAL_GPIO_Init(GPIOE, &GPIO_InitStruct);

  /*Configure GPIO pin : USER_Btn_Pin */
  GPIO_InitStruct.Pin = USER_Btn_Pin;
  GPIO_InitStruct.Mode = GPIO_MODE_IT_RISING;
  GPIO_InitStruct.Pull = GPIO_NOPULL;
  HAL_GPIO_Init(USER_Btn_GPIO_Port, &GPIO_InitStruct);

  /*Configure GPIO pins : PF2 PF11 PF12 PF13
                           PF14 PF15 */
  GPIO_InitStruct.Pin = GPIO_PIN_2|GPIO_PIN_11|GPIO_PIN_12|GPIO_PIN_13
                          |GPIO_PIN_14|GPIO_PIN_15;
  GPIO_InitStruct.Mode = GPIO_MODE_INPUT;
  GPIO_InitStruct.Pull = GPIO_NOPULL;
  HAL_GPIO_Init(GPIOF, &GPIO_InitStruct);

  /*Configure GPIO pins : LD1_Pin LD2_Pin */
  GPIO_InitStruct.Pin = LD1_Pin|LD2_Pin;
  GPIO_InitStruct.Mode = GPIO_MODE_OUTPUT_PP;
  GPIO_InitStruct.Pull = GPIO_NOPULL;
  GPIO_InitStruct.Speed = GPIO_SPEED_FREQ_LOW;
  HAL_GPIO_Init(GPIOB, &GPIO_InitStruct);

  /*Configure GPIO pins : PG0 PG1 PG2 PG3
                           PG4 PG5 PG6 USB_OverCurrent_Pin
                           PG8 PG9 PG10 PG12
                           PG14 PG15 */
  GPIO_InitStruct.Pin = GPIO_PIN_0|GPIO_PIN_1|GPIO_PIN_2|GPIO_PIN_3
                          |GPIO_PIN_4|GPIO_PIN_5|GPIO_PIN_6|USB_OverCurrent_Pin
                          |GPIO_PIN_8|GPIO_PIN_9|GPIO_PIN_10|GPIO_PIN_12
                          |GPIO_PIN_14|GPIO_PIN_15;
  GPIO_InitStruct.Mode = GPIO_MODE_INPUT;
  GPIO_InitStruct.Pull = GPIO_NOPULL;
  HAL_GPIO_Init(GPIOG, &GPIO_InitStruct);

  /*Configure GPIO pins : PB12 PB8 */
  GPIO_InitStruct.Pin = GPIO_PIN_12|GPIO_PIN_8;
  GPIO_InitStruct.Mode = GPIO_MODE_INPUT;
  GPIO_InitStruct.Pull = GPIO_NOPULL;
  HAL_GPIO_Init(GPIOB, &GPIO_InitStruct);

  /*Configure GPIO pin : RMII_TXD1_Pin */
  GPIO_InitStruct.Pin = RMII_TXD1_Pin;
  GPIO_InitStruct.Mode = GPIO_MODE_AF_PP;
  GPIO_InitStruct.Pull = GPIO_NOPULL;
  GPIO_InitStruct.Speed = GPIO_SPEED_FREQ_VERY_HIGH;
  GPIO_InitStruct.Alternate = GPIO_AF11_ETH;
  HAL_GPIO_Init(RMII_TXD1_GPIO_Port, &GPIO_InitStruct);

  /*Configure GPIO pins : PD10 PD11 PD14 PD15
                           PD3 PD4 */
  GPIO_InitStruct.Pin = GPIO_PIN_10|GPIO_PIN_11|GPIO_PIN_14|GPIO_PIN_15
                          |GPIO_PIN_3|GPIO_PIN_4;
  GPIO_InitStruct.Mode = GPIO_MODE_OUTPUT_PP;
  GPIO_InitStruct.Pull = GPIO_NOPULL;
  GPIO_InitStruct.Speed = GPIO_SPEED_FREQ_LOW;
  HAL_GPIO_Init(GPIOD, &GPIO_InitStruct);

  /*Configure GPIO pins : USB_SOF_Pin USB_ID_Pin USB_DM_Pin USB_DP_Pin */
  GPIO_InitStruct.Pin = USB_SOF_Pin|USB_ID_Pin|USB_DM_Pin|USB_DP_Pin;
  GPIO_InitStruct.Mode = GPIO_MODE_AF_PP;
  GPIO_InitStruct.Pull = GPIO_NOPULL;
  GPIO_InitStruct.Speed = GPIO_SPEED_FREQ_VERY_HIGH;
  GPIO_InitStruct.Alternate = GPIO_AF10_OTG_FS;
  HAL_GPIO_Init(GPIOA, &GPIO_InitStruct);

  /*Configure GPIO pin : USB_VBUS_Pin */
  GPIO_InitStruct.Pin = USB_VBUS_Pin;
  GPIO_InitStruct.Mode = GPIO_MODE_INPUT;
  GPIO_InitStruct.Pull = GPIO_NOPULL;
  HAL_GPIO_Init(USB_VBUS_GPIO_Port, &GPIO_InitStruct);

  /*Configure GPIO pin : PC12 */
  GPIO_InitStruct.Pin = GPIO_PIN_12;
  GPIO_InitStruct.Mode = GPIO_MODE_INPUT;
  GPIO_InitStruct.Pull = GPIO_NOPULL;
  HAL_GPIO_Init(GPIOC, &GPIO_InitStruct);

  /*Configure GPIO pins : PD2 PD5 PD6 PD7 */
  GPIO_InitStruct.Pin = GPIO_PIN_2|GPIO_PIN_5|GPIO_PIN_6|GPIO_PIN_7;
  GPIO_InitStruct.Mode = GPIO_MODE_INPUT;
  GPIO_InitStruct.Pull = GPIO_NOPULL;
  HAL_GPIO_Init(GPIOD, &GPIO_InitStruct);

  /*Configure GPIO pins : RMII_TX_EN_Pin RMII_TXD0_Pin */
  GPIO_InitStruct.Pin = RMII_TX_EN_Pin|RMII_TXD0_Pin;
  GPIO_InitStruct.Mode = GPIO_MODE_AF_PP;
  GPIO_InitStruct.Pull = GPIO_NOPULL;
  GPIO_InitStruct.Speed = GPIO_SPEED_FREQ_VERY_HIGH;
  GPIO_InitStruct.Alternate = GPIO_AF11_ETH;
  HAL_GPIO_Init(GPIOG, &GPIO_InitStruct);

  /*Configure GPIO pins : PB4 PB5 */
  GPIO_InitStruct.Pin = GPIO_PIN_4|GPIO_PIN_5;
  GPIO_InitStruct.Mode = GPIO_MODE_AF_PP;
  GPIO_InitStruct.Pull = GPIO_NOPULL;
  GPIO_InitStruct.Speed = GPIO_SPEED_FREQ_LOW;
  GPIO_InitStruct.Alternate = GPIO_AF2_TIM3;
  HAL_GPIO_Init(GPIOB, &GPIO_InitStruct);

}

void Error_Handler(void)
{
  __disable_irq();
  while (1)
  {
  }
}
